# PY32F002Axx register map
Vendor: Puya; Series: PY32F0; File version: 1.0.0
CPU: CM0+ r0p1, little endian, no MPU, no FPU, 4 interrupt priority bits
Registers are 32-bit, read-write, reset 0x0 unless marked. A register's access mark holds for its fields unless they carry their own. Offsets are from the block's base; [hi:lo] are bit positions; {n}, {i} and the like mark numbered series.

## COMP2 — Comparator
Base 0x40010210
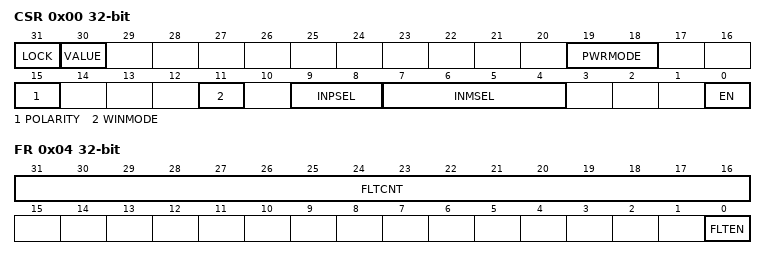
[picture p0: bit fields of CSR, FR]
0x00 CSR — COMP control and status register
  [31] LOCK — CSR register lock
    0=Unlocked (Comparator CSR bits are read-write); 1=Locked (Comparator CSR bits are read-only)
  [30] VALUE — Comparator output status
    on read: 0=Low (Comparator output is low); 1=High (Comparator output is high)
  [19:18] PWRMODE — Comparator power mode selector
    0=High speed / full power; 1=Medium speed / medium power; 2=Low speed / low power; 3=Very-low speed / ultra-low power
  [15] POLARITY — Comparator polarity selector
    0=NotInverted (Output is not inverted); 1=Inverted (Output is inverted)
  [11] WINMODE — Comparator non-inverting input selector for window mode
    0=Disabled (COMP2 non-inverting input is not connected to COMP1_INP); 1=Enabled (COMP2 non-inverting input is connected to COMP1_INP)
  [9:8] INPSEL — Comparator signal selector for non-inverting input
    0=PB4 (PB4 connected to non-inverting input); 1=PB6 (PB6 connected to non-inverting input); 2=PA3 (PA3 connected to non-inverting input); 3=PF3 (PF3 connected to non-inverting input)
  [7:4] INMSEL — Comparator signal selector for inverting input INM
    0=OneQuarterVRef (1/4 of VRefint); 1=ThreeQuarterVRef (3/4 of VRefint); 2=OneHalfVRef (1/2 of VRefint); 3=VRefint; 4=Vcc; 5=TS; 6=PB3 (PB3 connected to inverting input); 7=PB7 (PB6 connected to inverting input); 8=PA2 (PA2 connected to inverting input)
  [0] EN — COMP enable bit
    0=Disabled (Comparator 1 disabled); 1=Enabled (Comparator 1 enabled)
0x04 FR — Comparator Filter register
  [31:16] FLTCNT — Comparator filter and counter
  [0] FLTEN — Filter enable bit
    0=Disabled (Comparator digital filter disabled); 1=Enabled (Comparator digital filter enabled)

## GPIOA — General-purpose I/Os
Base 0x50000000
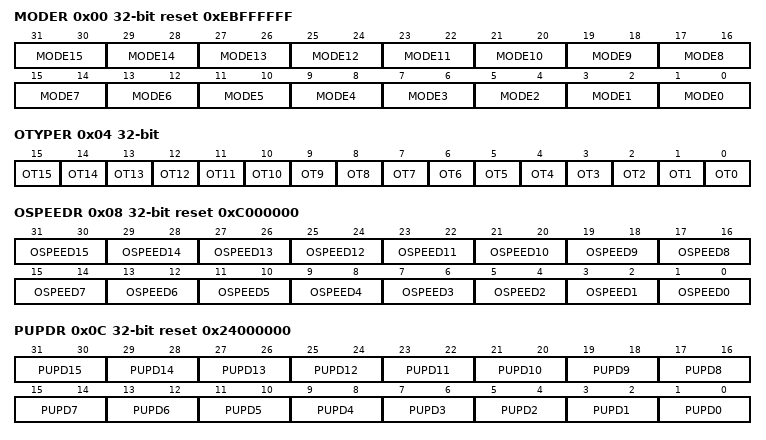
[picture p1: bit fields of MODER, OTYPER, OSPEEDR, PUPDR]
0x00 MODER reset 0xEBFFFFFF — GPIO port mode register
  [all] fields
    0=Input mode; 1=Output (General purpose output mode); 2=Alternate function mode; 3=Analog mode
  [2n+1:2n] MODE{n} (n=0..15) — Port x configuration bits (y = 0..15)
0x04 OTYPER — GPIO port output type register
  [all] fields
    0=PushPull (Output push-pull (reset state)); 1=OpenDrain (Output open-drain)
  [n] OT{n} (n=0..15) — Port x configuration bits (y = 0..15)
0x08 OSPEEDR reset 0xC000000 — GPIO port output speed register
  [all] fields
    0=LowSpeed; 1=MediumSpeed; 2=HighSpeed; 3=VeryHighSpeed
  [2n+1:2n] OSPEED{n} (n=0..15) — Port x configuration bits (y = 0..15)
0x0C PUPDR reset 0x24000000 — GPIO port pull-up/pull-down register
  [all] fields
    0=Floating (No pull-up, pull-down); 1=PullUp; 2=PullDown
  [2n+1:2n] PUPD{n} (n=0..15) — Port x configuration bits (y = 0..15)
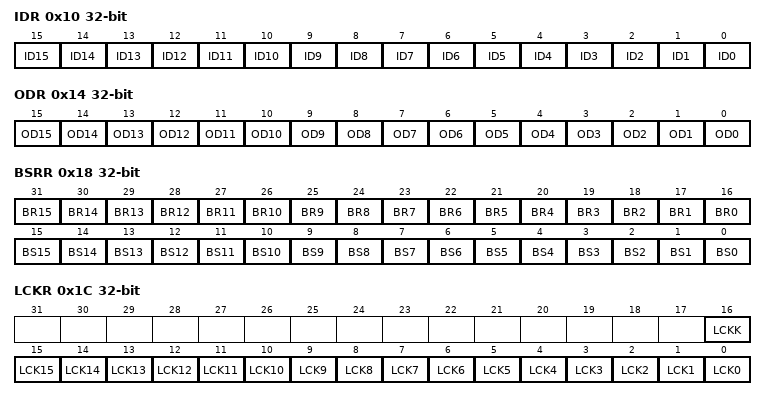
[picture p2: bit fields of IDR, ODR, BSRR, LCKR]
0x10 IDR ro — GPIO port input data register
  [all] fields
    0=Low (Input is logic low); 1=High (Input is logic high)
  [n] ID{n} (n=0..15) — Port input data (y = 0..15)
0x14 ODR — GPIO port output data register
  [all] fields
    0=Low (Set output to logic low); 1=High (Set output to logic high)
  [n] OD{n} (n=0..15) — Port output data (y = 0..15)
0x18 BSRR wo — GPIO port bit set/reset register
  [n+16] BR{n} (n=1..15) — Port x reset bit y (y = 0..15)
    1=Resets the corresponding ODx bit
  [16] BR0 — Port x set bit y (y= 0..15)
    1=Resets the corresponding ODx bit
  [n] BS{n} (n=0..15) — Port x set bit y (y= 0..15)
    1=Set (Sets the corresponding ODx bit)
0x1C LCKR — GPIO port configuration lock register
  [16] LCKK — Port x lock bit y (y= 0..15)
    0=NotActive (Port configuration lock key not active); 1=Active (Port configuration lock key active)
  [n] LCK{n} (n=0..15) — Port x lock bit y (y= 0..15)
    0=Unlocked (Port configuration not locked); 1=Locked (Port configuration locked)
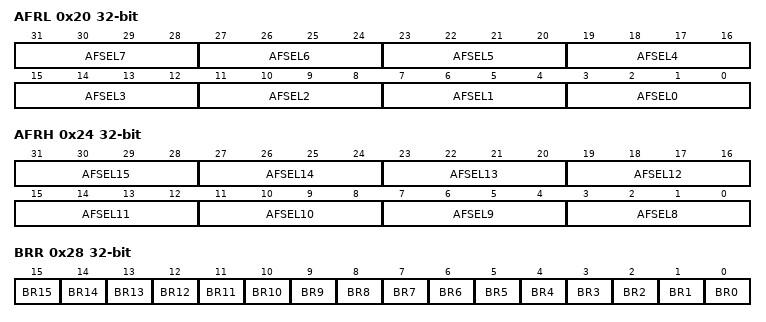
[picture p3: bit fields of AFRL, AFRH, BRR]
0x20 AFRL — GPIO alternate function low register
  [all] fields
    {v}=AF{v} (v=0..15)
  [4n+3:4n] AFSEL{n} (n=0..7) — Alternate function selection for port x bit y (y = 0..7)
0x24 AFRH — GPIO alternate function high register
  [all] fields
    {v}=AF{v} (v=0..15)
  [4n-29:4n-32] AFSEL{n} (n=8..15) — Alternate function selection for port x bit y (y = 8..15)
0x28 BRR wo — port bit reset register
  [all] fields
    0=No action on the corresponding ODx bit; 1=Reset the ODx bit
  [n] BR{n} (n=0..15) — Port Reset bit
